VERSION ""

NS_ :

BS_:

BU_: ECU_2 ECU_1

BO_ 34 Engine: 2 ECU_2
 SG_ Rpm : 8|8@1+ (1,0) [0|255] "" Vector__XXX
 SG_ Temperature : 0|8@1+ (1,0) [0|255] "" Vector__XXX

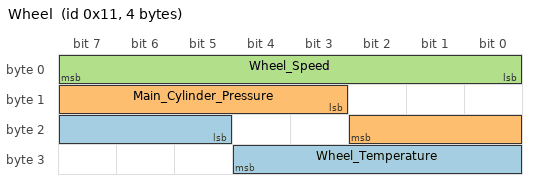
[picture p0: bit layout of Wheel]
BO_ 17 Wheel: 4 ECU_2
 SG_ Wheel_Temperature : 21|8@1+ (1,2) [0|255] "" Vector__XXX
 SG_ Main_Cylinder_Pressure : 11|8@1+ (1,3) [0|255] "" Vector__XXX
 SG_ Wheel_Speed : 0|8@1+ (1,0) [0|255] "" Vector__XXX

BA_DEF_ BO_  "GenMsgCycleTime" INT 0 1000;
BA_DEF_  "BusType" STRING ;
BA_DEF_DEF_  "GenMsgCycleTime" 500;
BA_DEF_DEF_  "BusType" "CAN";
BA_ "GenMsgCycleTime" BO_ 17 350;
